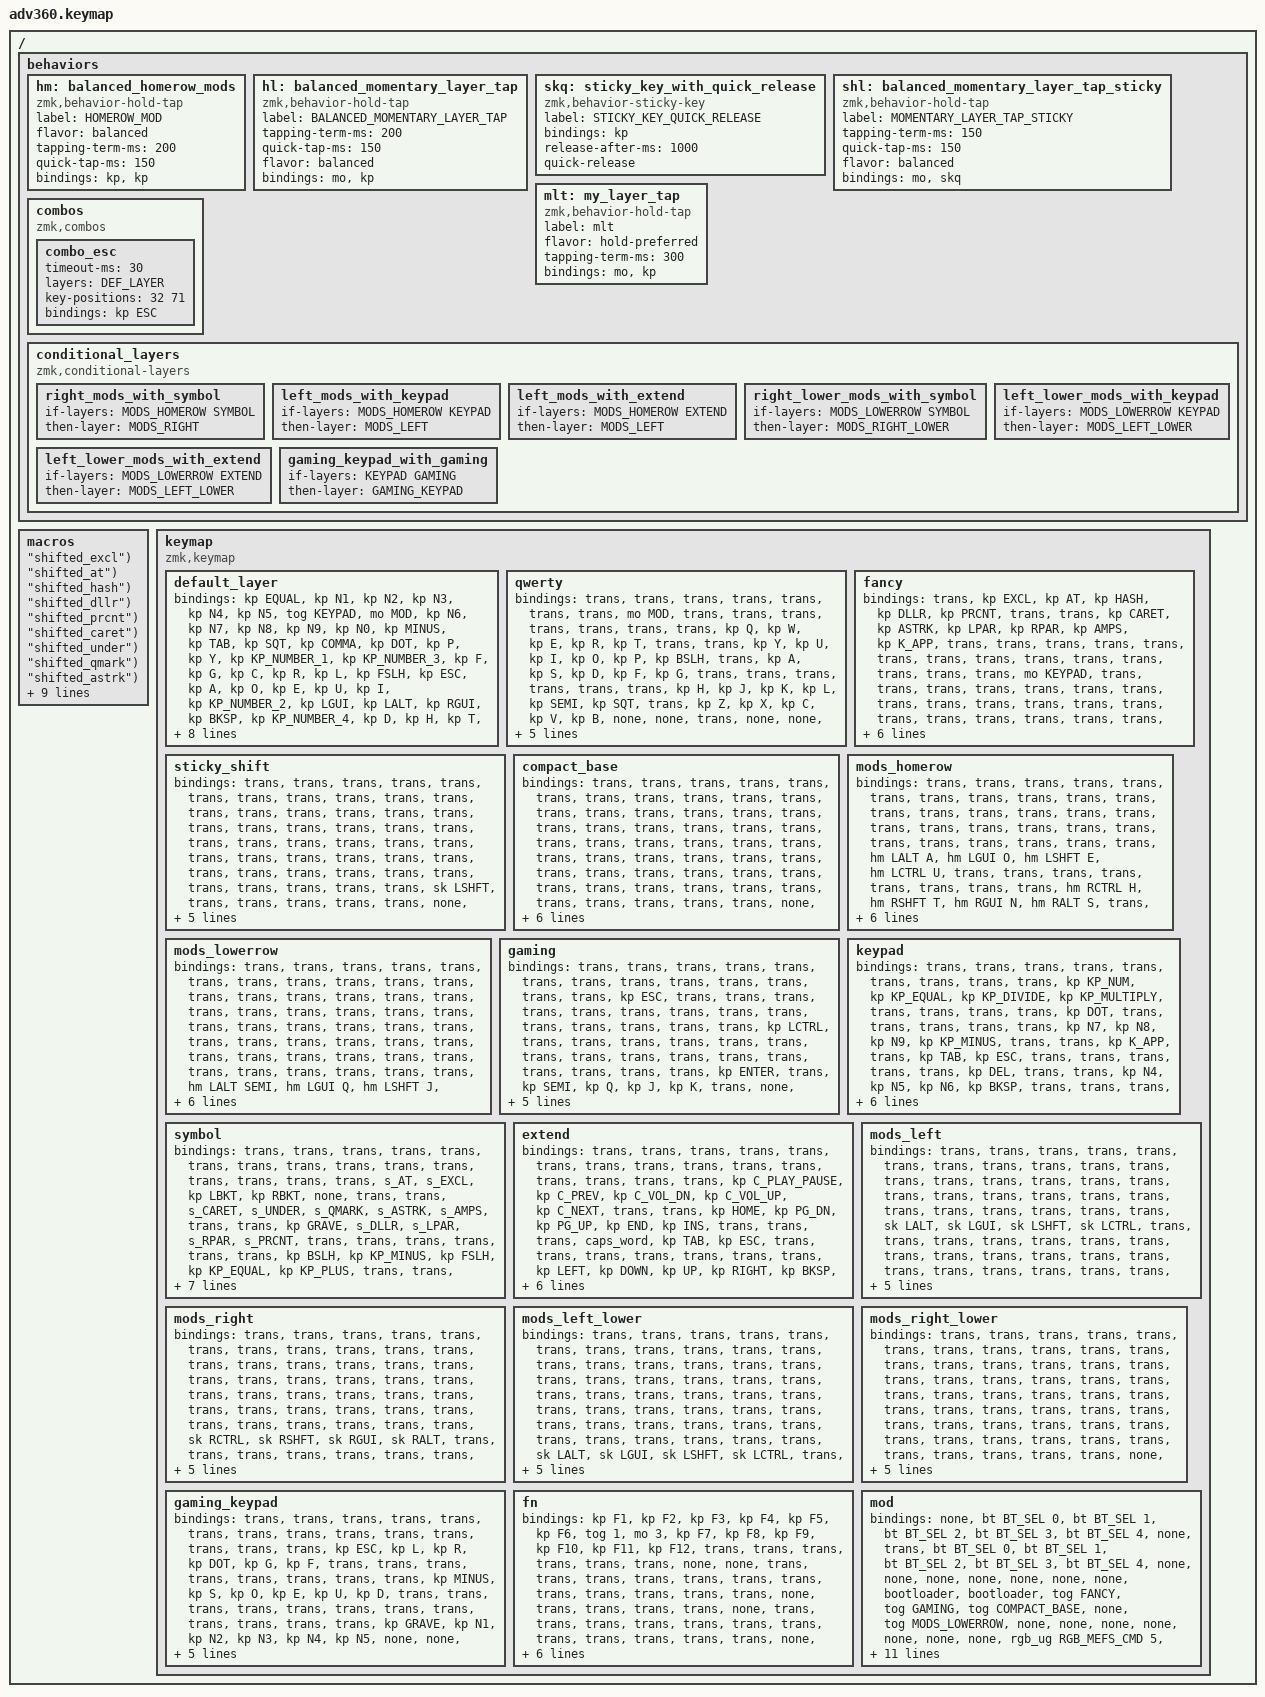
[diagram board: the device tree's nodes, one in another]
#include <behaviors.dtsi>
#include <dt-bindings/zmk/keys.h>
#include <dt-bindings/zmk/bt.h>
#include <dt-bindings/zmk/rgb.h>
#include <dt-bindings/zmk/backlight.h>

#define DEF_LAYER         0
#define QWERTY            1
#define FANCY             2
#define STICKY_SHIFT      3
#define COMPACT_BASE      4
#define MODS_HOMEROW      5
#define MODS_LOWERROW     6
#define GAMING            7
#define KEYPAD            8
#define SYMBOL            9
#define EXTEND            10
#define MODS_LEFT         11
#define MODS_RIGHT        12
#define MODS_LEFT_LOWER   13
#define MODS_RIGHT_LOWER  14
#define GAMING_KEYPAD     15
#define FN                16
#define MOD               17 

/**
 * Shifted keys, like `&kp lpar`, do not work consistently in Gnome with
 * Wayland. I believe the problem is that ZMK sends key press and release events
 * without any delays in between, and libinput is a bit sloppy with event
 * processing order. A workaround is to define a macro which includes
 * a deliberate delay between steps. But that requires defining a separate macro
 * for each shifted key you want to map.
 *
 * This defines a preprocessor macro to make it as easy as possible to define
 * a lot of ZMK macros for shifted keys.
 */
#define SHIFTED(sym, macro_label) s_##sym: s_##sym {\
        label = macro_label;\
        compatible = "zmk,behavior-macro";\
        wait-ms = <50>;\
        #binding-cells = <0>;\
        bindings\
            = <&macro_press &kp LSHFT>\
            , <&macro_press &kp sym>\
            , <&macro_release &kp LSHFT>\
            , <&macro_pause_for_release>\
            , <&macro_release &kp sym>\
            ;\
    }

/ {
    behaviors {
      #include "macros.dtsi"

      hm: balanced_homerow_mods {
          compatible = "zmk,behavior-hold-tap";
          label = "HOMEROW_MOD";
          #binding-cells = <2>;
          flavor = "balanced";
          tapping-term-ms = <200>;    // <---[[moderate duration]]
          quick-tap-ms = <150>;
          bindings = <&kp>, <&kp>;
      };

      hl: balanced_momentary_layer_tap {
          compatible = "zmk,behavior-hold-tap";
          label = "BALANCED_MOMENTARY_LAYER_TAP";
          #binding-cells = <2>;
          tapping-term-ms = <200>;    // <---[[moderate duration]]
          quick-tap-ms = <150>;
          flavor = "balanced";
          bindings = <&mo>, <&kp>;
      };

      skq: sticky_key_with_quick_release {
	 compatible = "zmk,behavior-sticky-key";
         label = "STICKY_KEY_QUICK_RELEASE";
         #binding-cells = <1>;
         bindings = <&kp>;
         release-after-ms = <1000>;
         quick-release;
      };

      shl: balanced_momentary_layer_tap_sticky {
          compatible = "zmk,behavior-hold-tap";
          label = "MOMENTARY_LAYER_TAP_STICKY";
          #binding-cells = <2>;
          tapping-term-ms = <150>;    // <---[[moderate duration]]
          quick-tap-ms = <150>;
          flavor = "balanced";
          bindings = <&mo>, <&skq>;
      };

      mlt: my_layer_tap {
          compatible = "zmk,behavior-hold-tap";
          label = "mlt";
          #binding-cells = <2>;
          flavor = "hold-preferred";
          tapping-term-ms = <300>;
          bindings = <&mo>, <&kp>;
      };

      combos {
        compatible = "zmk,combos";
        // I input escape by holding space, and typing U. I like to do that
        // quickly in a rolling press which the firmware interprets as a tap so
        // it invokes the space behavior of the key instead of the layer shift.
        // I don't think I can tweak the hold-tap settings to make this work,
        // and still have a functional space key. So I have this combo for
        // special-case, simultaneous pressing of these two keys.
        combo_esc {
          timeout-ms = <30>;
          layers = <DEF_LAYER>;
          key-positions = <32 71>; // 32 is U, 71 is space/extend
          bindings = <&kp ESC>;
        };
      };

      conditional_layers {
          compatible = "zmk,conditional-layers";
          right_mods_with_symbol {
            if-layers = <MODS_HOMEROW SYMBOL>;
            then-layer = <MODS_RIGHT>;
          };
          left_mods_with_keypad {
            if-layers = <MODS_HOMEROW KEYPAD>;
            then-layer = <MODS_LEFT>;
          };
          left_mods_with_extend {
            if-layers = <MODS_HOMEROW EXTEND>;
            then-layer = <MODS_LEFT>;
          };
          right_lower_mods_with_symbol {
            if-layers = <MODS_LOWERROW SYMBOL>;
            then-layer = <MODS_RIGHT_LOWER>;
          };
          left_lower_mods_with_keypad {
            if-layers = <MODS_LOWERROW KEYPAD>;
            then-layer = <MODS_LEFT_LOWER>;
          };
          left_lower_mods_with_extend {
            if-layers = <MODS_LOWERROW EXTEND>;
            then-layer = <MODS_LEFT_LOWER>;
          };
          gaming_keypad_with_gaming {
            if-layers = <KEYPAD GAMING>;
            then-layer = <GAMING_KEYPAD>;
          };
      };
    };

  macros {
    SHIFTED(EXCL, "shifted_excl");
    SHIFTED(AT, "shifted_at");
    SHIFTED(HASH, "shifted_hash");
    SHIFTED(DLLR, "shifted_dllr");
    SHIFTED(PRCNT, "shifted_prcnt");
    SHIFTED(CARET, "shifted_caret");
    SHIFTED(UNDER, "shifted_under");
    SHIFTED(QMARK, "shifted_qmark");
    SHIFTED(ASTRK, "shifted_astrk");
    SHIFTED(AMPS, "shifted_amps");
    SHIFTED(TILDE, "shifted_tilde");
    SHIFTED(LBRC, "shifted_lbrc");
    SHIFTED(RBRC, "shifted_rbrc");
    SHIFTED(LPAR, "shifted_lpar");
    SHIFTED(RPAR, "shifted_rpar");
    SHIFTED(LT, "shifted_lt");
    SHIFTED(GT, "shifted_gt");
    SHIFTED(PIPE, "shifted_pipe");
  };

  keymap {
    compatible = "zmk,keymap";

    default_layer {
      bindings = <
        &kp EQUAL &kp N1    &kp N2    &kp N3   &kp N4     &kp N5 &tog KEYPAD                                                                &mo MOD         &kp N6 &kp N7 &kp N8    &kp N9   &kp N0   &kp MINUS
        &kp TAB   &kp SQT   &kp COMMA &kp DOT  &kp P      &kp Y  &kp KP_NUMBER_1                                                            &kp KP_NUMBER_3 &kp F  &kp G  &kp C     &kp R    &kp L    &kp FSLH
        &kp ESC   &kp A     &kp O     &kp E    &kp U      &kp I  &kp KP_NUMBER_2   &kp LGUI  &kp LALT             &kp RGUI  &kp BKSP        &kp KP_NUMBER_4 &kp D  &kp H  &kp T     &kp N    &kp S    &kp MINUS
        &kp LSHFT &kp SEMI  &kp Q     &kp J    &kp K      &kp X          &none     &none     &kp HOME &none &none &kp PG_UP &none    &none                  &kp B  &kp M  &kp W     &kp V    &kp Z    &kp RSHFT
        &mo FN    &kp GRAVE &kp BSLH  &kp LEFT &kp RIGHT                 &kp SPACE &kp LCTRL &kp END              &kp PG_DN &kp RCTL &kp ENTER                     &kp UP &kp DOWN  &kp LBKT &kp RBKT &mo FN 
        >;
    };
    qwerty {
      bindings = <
        &trans &trans &trans &trans &trans &trans &trans                                                       &mo MOD &trans &trans &trans    &trans  &trans   &trans
        &trans &kp Q  &kp W  &kp E  &kp R  &kp T  &trans                                                       &trans  &kp Y  &kp U  &kp I     &kp O   &kp P    &kp BSLH
        &trans &kp A  &kp S  &kp D  &kp F  &kp G  &trans        &trans &trans             &trans &trans        &trans  &kp H  &kp J  &kp K     &kp L   &kp SEMI &kp SQT
        &trans &kp Z  &kp X  &kp C  &kp V  &kp B         &none  &none  &trans &none &none &trans &none  &none          &kp N  &kp M  &kp COMMA &kp DOT &kp FSLH &trans
        &trans &trans &trans &trans &trans               &trans &trans &trans             &trans &trans &trans                &trans &trans    &trans  &trans   &trans
        >;
    };
    fancy {
      bindings = <
        &trans      &kp EXCL &kp AT &kp HASH &kp DLLR &kp PRCNT &trans                                                                    &trans  &kp CARET &kp ASTRK &kp LPAR &kp RPAR &kp AMPS &kp K_APP
        &trans      &trans   &trans &trans   &trans   &trans    &trans                                                                    &trans  &trans    &trans    &trans   &trans   &trans   &trans
        &mo KEYPAD  &trans   &trans &trans   &trans   &trans    &trans        &trans        &trans             &trans &trans              &trans  &trans    &trans    &trans   &trans   &trans   &trans
        &trans      &trans   &trans &trans   &trans   &trans           &none  &none         &trans &none &none &trans &none        &none          &trans    &trans    &trans   &trans   &trans   &trans
        &trans      &trans   &trans &trans   &trans                    &trans &mt LCTRL ESC &trans             &trans &mt RCTL ESC &trans                   &trans    &trans   &trans   &trans   &trans
      >;
    };
    sticky_shift {
      bindings = <
        &trans    &trans &trans &trans &trans &trans &trans                                                       &trans &trans &trans &trans &trans &trans &trans
        &trans    &trans &trans &trans &trans &trans &trans                                                       &trans &trans &trans &trans &trans &trans &trans
        &trans    &trans &trans &trans &trans &trans &trans        &trans &trans             &trans &trans        &trans &trans &trans &trans &trans &trans &trans
        &sk LSHFT &trans &trans &trans &trans &trans        &none  &none  &trans &none &none &trans &none  &none         &trans &trans &trans &trans &trans &sk RSHFT
        &trans    &trans &trans &trans &trans               &trans &trans &trans             &trans &trans &trans               &trans &trans &trans &trans &trans
      >;
    };
    compact_base {
      bindings = <
        &trans &trans      &trans      &trans       &trans       &trans &trans                                                                              &trans &trans &trans       &trans       &trans      &trans      &trans
        &trans &trans      &trans      &trans       &trans       &trans &trans                                                                              &trans &trans &trans       &trans       &trans      &trans      &trans
        &trans &trans      &trans      &trans       &trans       &trans &trans                   &trans     &trans             &trans &trans                &trans &trans &trans       &trans       &trans      &trans      &trans
        &trans &trans      &trans      &trans       &trans       &trans        &none             &none      &trans &none &none &trans &none      &none             &trans &trans       &trans       &trans      &trans      &trans
        &trans &trans      &trans      &trans       &trans                     &hl EXTEND SPACE  &sl KEYPAD &trans             &trans &skq LSHFT &sl SYMBOL               &trans       &trans       &trans      &trans      &trans
      >;
    };
    mods_homerow {
      bindings = <
        &trans &trans      &trans      &trans       &trans       &trans &trans                                                          &trans &trans &trans       &trans       &trans      &trans      &trans
        &trans &trans      &trans      &trans       &trans       &trans &trans                                                          &trans &trans &trans       &trans       &trans      &trans      &trans
        &trans &hm LALT A  &hm LGUI O  &hm LSHFT E  &hm LCTRL U  &trans &trans         &trans  &trans             &trans &trans         &trans &trans &hm RCTRL H  &hm RSHFT T  &hm RGUI N  &hm RALT S  &trans
        &trans &trans      &trans      &trans       &trans       &trans        &none   &none   &trans &none &none &trans &none   &none         &trans &trans       &trans       &trans      &trans      &trans
        &trans &trans      &trans      &trans       &trans                     &trans  &trans  &trans             &trans &trans  &trans               &trans       &trans       &trans      &trans      &trans
      >;
    };
    mods_lowerrow {
      bindings = <
        &trans &trans         &trans      &trans       &trans       &trans &trans                                                          &trans &trans &trans       &trans       &trans      &trans      &trans
        &trans &trans         &trans      &trans       &trans       &trans &trans                                                          &trans &trans &trans       &trans       &trans      &trans      &trans
        &trans &trans         &trans      &trans       &trans       &trans &trans         &trans  &trans             &trans &trans         &trans &trans &trans       &trans       &trans      &trans      &trans
        &trans &hm LALT SEMI  &hm LGUI Q  &hm LSHFT J  &hm LCTRL K  &trans        &none   &none   &trans &none &none &trans &none   &none         &trans &hm RCTRL M  &hm RSHFT W  &hm RGUI V  &hm RALT Z  &trans
        &trans &trans         &trans      &trans       &trans                     &trans  &trans  &trans             &trans &trans  &trans               &trans       &trans       &trans      &trans      &trans
      >;
    };
    gaming {
      bindings = <
        &trans    &trans   &trans &trans &trans &trans &trans                                                                  &trans &trans &trans &trans &trans &trans &kp ESC
        &trans    &trans   &trans &trans &trans &trans &trans                                                                  &trans &trans &trans &trans &trans &trans &trans
        &kp LCTRL &trans   &trans &trans &trans &trans &trans            &trans &trans               &trans     &trans         &trans &trans &trans &trans &trans &trans &kp ENTER
        &trans    &kp SEMI &kp Q  &kp J  &kp K  &trans        &none      &none  &trans   &none &none &trans     &none   &none         &trans &trans &trans &trans &trans &trans
        &trans    &trans   &trans &trans &trans               &kp SPACE  &trans &kp BKSP             &mo EXTEND &trans  &trans               &trans &trans &trans &trans &trans
      >;
    };
    keypad {
      bindings = <
        &trans &trans    &trans     &trans  &trans  &trans &trans                                                        &trans  &trans &kp KP_NUM &kp KP_EQUAL &kp KP_DIVIDE &kp KP_MULTIPLY &trans
        &trans &trans    &trans     &kp DOT &trans  &trans &trans                                                        &trans  &trans &kp N7     &kp N8       &kp N9        &kp KP_MINUS    &trans
        &trans &kp K_APP &trans     &kp TAB &kp ESC &trans &trans        &trans &trans             &trans &kp DEL        &trans  &trans &kp N4     &kp N5       &kp N6        &kp BKSP        &trans
        &trans &trans    &trans     &trans  &trans  &trans        &none  &none  &trans &none &none &trans &none   &none          &trans &kp N1     &kp N2       &kp N3        &kp KP_PLUS     &trans
        &trans &trans    &kp INSERT &trans  &trans                &trans &trans &trans             &trans &trans  &kp N0                &trans     &trans       &kp KP_DOT    &kp KP_ENTER    &trans 
      >;
    };
    symbol {
      bindings = <
        &trans  &trans    &trans  &trans   &trans   &trans   &trans                                                           &trans &trans   &trans       &trans    &trans       &trans      &trans
        &trans  &s_AT     &s_EXCL &kp LBKT &kp RBKT &none    &trans                                                           &trans &s_CARET &s_UNDER     &s_QMARK  &s_ASTRK     &s_AMPS     &trans
        &trans  &kp GRAVE &s_DLLR &s_LPAR  &s_RPAR  &s_PRCNT &trans            &trans &trans             &trans &trans        &trans &kp BSLH &kp KP_MINUS &kp FSLH  &kp KP_EQUAL &kp KP_PLUS &trans
        &trans  &s_TILDE  &s_HASH &s_LBRC  &s_RBRC  &none            &none     &none  &trans &none &none &trans &none  &none         &s_PIPE  &kp KP_MINUS &kp FSLH  &kp KP_EQUAL &kp KP_PLUS &trans
        &trans  &trans    &trans  &trans   &trans                    &kp ENTER &trans &trans             &trans &trans &trans                 &trans       &trans    &trans       &trans      &trans
      >;
    };
    extend {
      bindings = <
        &trans  &trans           &trans       &trans        &trans        &trans      &trans                                                       &trans &trans   &trans    &trans    &trans    &trans   &trans
        &trans  &kp C_PLAY_PAUSE &kp C_PREV   &kp C_VOL_DN  &kp C_VOL_UP  &kp C_NEXT  &trans                                                       &trans &kp HOME &kp PG_DN &kp PG_UP &kp END   &kp INS  &trans
        &trans  &trans           &caps_word   &kp TAB       &kp ESC       &trans      &trans        &trans &trans             &trans &trans        &trans &kp LEFT &kp DOWN  &kp UP    &kp RIGHT &kp BKSP &trans
        &trans  &trans           &trans       &kp TAB       &kp TAB       &trans             &none  &none  &trans &none &none &trans &none  &none         &trans   &trans    &trans    &trans    &kp DEL  &trans
        &trans  &trans           &trans       &trans        &trans                           &trans &trans &trans             &trans &trans &kp ENTER              &trans    &trans    &trans    &trans   &trans
      >;
    };
    mods_left {
      bindings = <
        &trans &trans   &trans   &trans    &trans    &trans &trans                                                        &trans  &trans &trans     &trans       &trans        &trans          &trans
        &trans &trans   &trans   &trans    &trans    &trans &trans                                                        &trans  &trans &trans     &trans       &trans        &trans          &trans
        &trans &sk LALT &sk LGUI &sk LSHFT &sk LCTRL &trans &trans        &trans &trans             &trans &trans         &trans  &trans &trans     &trans       &trans        &trans          &trans
        &trans &trans   &trans   &trans    &trans    &trans        &none  &none  &trans &none &none &trans &none   &none          &trans &trans     &trans       &trans        &trans          &trans
        &trans &trans   &trans   &trans    &trans                  &trans &trans &trans             &trans &trans  &trans                &trans     &trans       &trans        &trans          &trans
      >;
    };
    mods_right {
      bindings = <
        &trans  &trans     &trans      &trans       &trans       &trans      &trans                                                       &trans &trans      &trans       &trans       &trans      &trans      &trans
        &trans  &trans     &trans      &trans       &trans       &trans      &trans                                                       &trans &trans      &trans       &trans       &trans      &trans      &trans
        &trans  &trans     &trans      &trans       &trans       &trans      &trans        &trans &trans             &trans &trans        &trans &trans      &sk RCTRL    &sk RSHFT    &sk RGUI    &sk RALT    &trans
        &trans  &trans     &trans      &trans       &trans       &trans             &none  &none  &trans &none &none &trans &none  &none         &trans      &trans       &trans       &trans      &trans      &trans
        &trans  &trans     &trans      &trans       &trans                          &trans &trans &trans             &trans &trans &trans                    &trans       &trans       &trans      &trans      &trans
      >;
    };
    mods_left_lower {
      bindings = <
        &trans &trans   &trans   &trans    &trans    &trans &trans                                                        &trans  &trans &trans     &trans       &trans        &trans          &trans
        &trans &trans   &trans   &trans    &trans    &trans &trans                                                        &trans  &trans &trans     &trans       &trans        &trans          &trans
        &trans &trans   &trans   &trans    &trans    &trans &trans        &trans &trans             &trans &trans         &trans  &trans &trans     &trans       &trans        &trans          &trans
        &trans &sk LALT &sk LGUI &sk LSHFT &sk LCTRL &trans        &none  &none  &trans &none &none &trans &none   &none          &trans &trans     &trans       &trans        &trans          &trans
        &trans &trans   &trans   &trans    &trans                  &trans &trans &trans             &trans &trans  &trans                &trans     &trans       &trans        &trans          &trans
      >;
    };
    mods_right_lower {
      bindings = <
        &trans  &trans     &trans      &trans       &trans       &trans      &trans                                                       &trans &trans      &trans       &trans       &trans      &trans      &trans
        &trans  &trans     &trans      &trans       &trans       &trans      &trans                                                       &trans &trans      &trans       &trans       &trans      &trans      &trans
        &trans  &trans     &trans      &trans       &trans       &trans      &trans        &trans &trans             &trans &trans        &trans &trans      &trans       &trans       &trans      &trans      &trans
        &trans  &trans     &trans      &trans       &trans       &trans             &none  &none  &trans &none &none &trans &none  &none         &trans      &sk RCTRL    &sk RSHFT    &sk RGUI    &sk RALT    &trans
        &trans  &trans     &trans      &trans       &trans                          &trans &trans &trans             &trans &trans &trans                    &trans       &trans       &trans      &trans      &trans
      >;
    };
    gaming_keypad {
      bindings = <
        &trans    &trans &trans &trans  &trans &trans &trans                                                        &trans  &trans &trans &trans &trans &trans &trans
        &kp ESC   &kp L  &kp R  &kp DOT &kp G  &kp F  &trans                                                        &trans  &trans &trans &trans &trans &trans &trans
        &kp MINUS &kp S  &kp O  &kp E   &kp U  &kp D  &trans        &trans &trans             &trans &trans         &trans  &trans &trans &trans &trans &trans &trans
        &kp GRAVE &kp N1 &kp N2 &kp N3  &kp N4 &kp N5        &none  &none  &trans &none &none &trans &none   &none          &trans &trans &trans &trans &trans &trans
        &trans    &trans &trans &trans  &trans               &trans &trans &trans             &trans &trans  &trans                &trans &trans &trans &trans &trans
      >;
    };
    fn {
      bindings = <
        &kp F1 &kp F2 &kp F3       &kp F4 &kp F5 &kp F6 &tog 1                                                                              &mo 3 &kp F7 &kp F8 &kp F9 &kp F10 &kp F11 &kp F12
        &trans &trans &trans       &trans &trans &trans  &none                                                                              &none &trans &trans &trans &trans  &trans  &trans
        &trans &trans &trans       &trans &trans &trans  &none                  &trans &trans                 &trans       &trans           &none &trans &trans &trans &trans  &trans  &trans
        &trans &trans &trans       &trans &trans &trans        &none            &none  &kp C_PREV &none &none &kp C_VOL_UP &none  &none           &trans &trans &trans &trans  &trans  &trans
        &trans &trans &kp CAPSLOCK &trans &trans               &kp C_PLAY_PAUSE &trans &kp C_NEXT             &kp C_VOL_DN &trans &trans                 &trans &trans &trans  &trans  &trans
      >;
    };
    mod {
      bindings = <
        &none &bt BT_SEL 0 &bt BT_SEL 1 &bt BT_SEL 2 &bt BT_SEL 3 &bt BT_SEL 4 &none                                                                                     &trans                 &bt BT_SEL 0  &bt BT_SEL 1      &bt BT_SEL 2      &bt BT_SEL 3 &bt BT_SEL 4       &none
        &none &none        &none        &none        &none        &none        &bootloader                                                                               &bootloader            &tog FANCY    &tog GAMING       &tog COMPACT_BASE &none        &tog MODS_LOWERROW &none
        &none &none        &none        &none        &none        &none        &rgb_ug RGB_MEFS_CMD 5     &bt BT_CLR &bt BT_CLR            &bt BT_CLR &bt BT_CLR         &rgb_ug RGB_MEFS_CMD 5 &to DEF_LAYER &tog MODS_HOMEROW &none             &none        &tog STICKY_SHIFT  &none
        &none &none        &to QWERTY   &none        &none        &none                   &none           &none      &none     &none &none &none      &none      &none                          &none         &none             &none             &none        &none              &none
        &none &none        &none        &bl BL_INC   &bl BL_DEC                           &rgb_ug RGB_TOG &bl BL_TOG &none                 &none      &bl BL_TOG &rgb_ug RGB_TOG                              &bl BL_INC        &bl BL_DEC        &none        &none              &none
      >;
    };
  };
};
